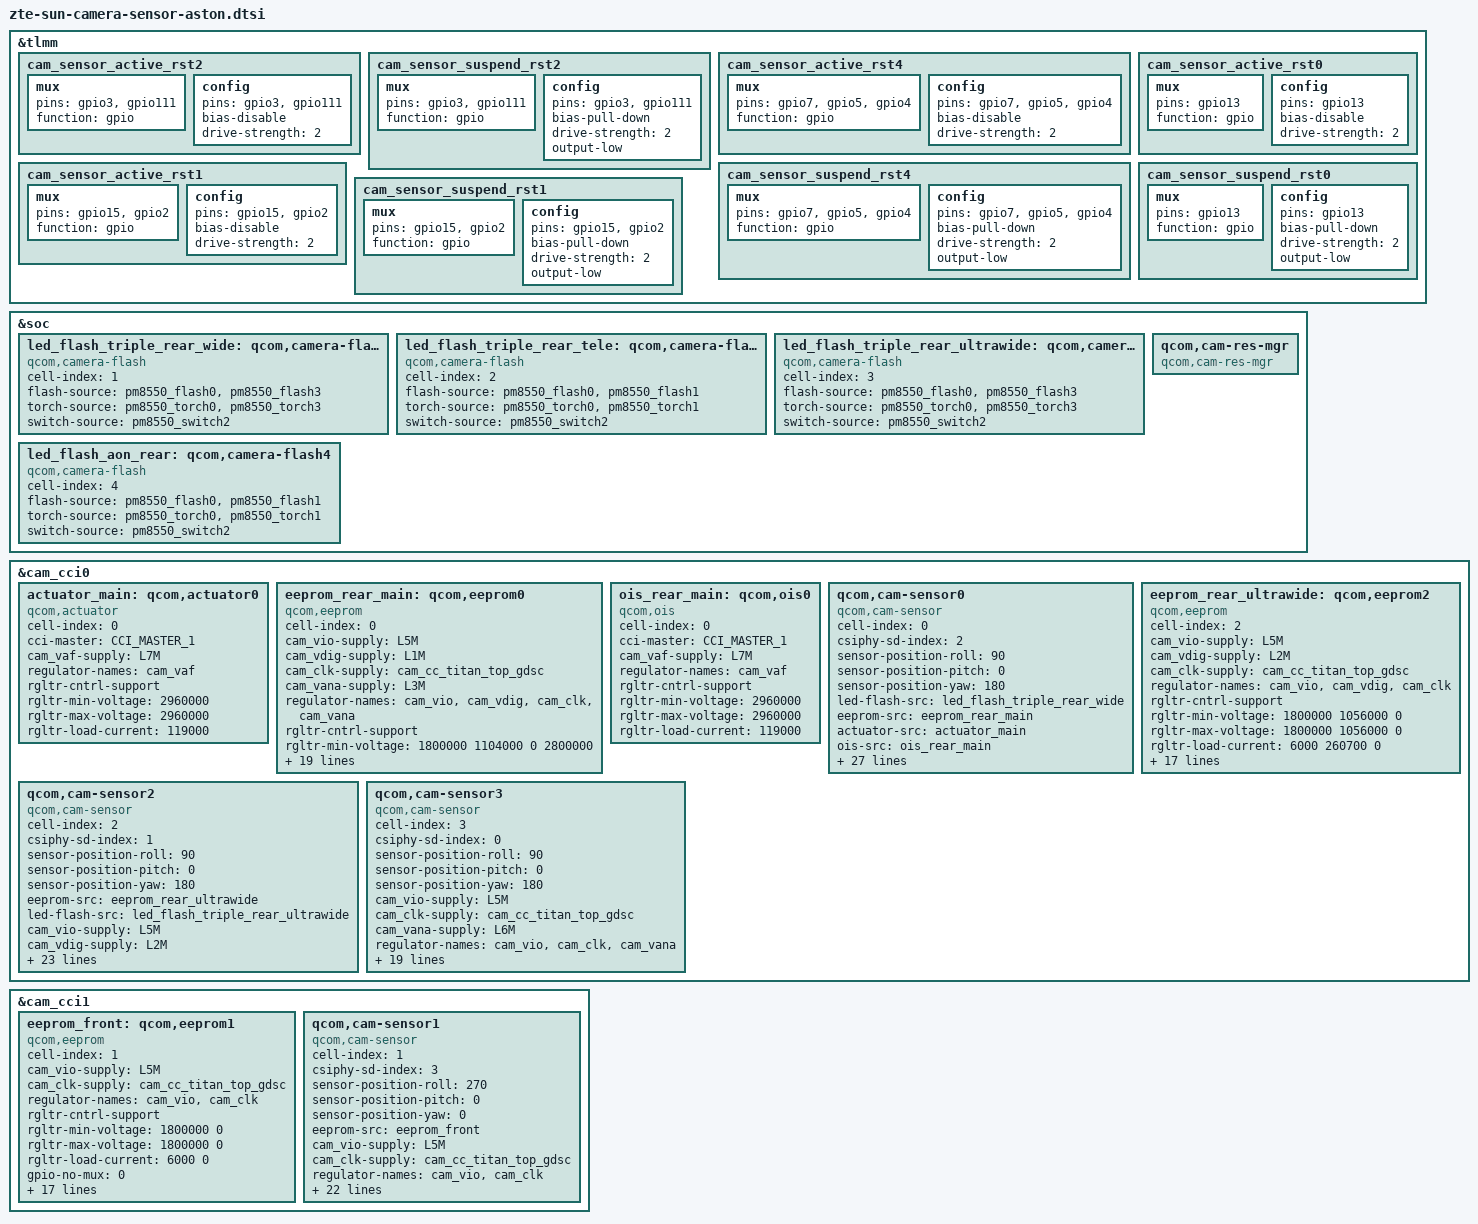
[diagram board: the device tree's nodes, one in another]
#include <dt-bindings/msm-camera.h>
&tlmm {
	cam_sensor_active_rst2: cam_sensor_active_rst2 {
		/* RESET 2 MAIN SENSOR*/
		mux {
			pins = "gpio3", "gpio111";
			function = "gpio";
		};

		config {
			pins = "gpio3", "gpio111";
			bias-disable; /* No PULL */
			drive-strength = <2>; /* 2 MA */
		};
	};

	cam_sensor_suspend_rst2: cam_sensor_suspend_rst2 {
		/* RESET 2 MAIN SENSOR*/
		mux {
			pins = "gpio3", "gpio111";
			function = "gpio";
		};

		config {
			pins = "gpio3", "gpio111";
			bias-pull-down; /* PULL DOWN */
			drive-strength = <2>; /* 2 MA */
			output-low;
		};
	};

	cam_sensor_active_rst4: cam_sensor_active_rst4 {
		/* RESET 4 FRONT SENSOR*/
		mux {
			pins = "gpio7", "gpio5", "gpio4";
			function = "gpio";
		};

		config {
			pins = "gpio7", "gpio5", "gpio4";
			bias-disable; /* No PULL */
			drive-strength = <2>; /* 2 MA */
		};
	};

	cam_sensor_suspend_rst4: cam_sensor_suspend_rst4 {
		/* RESET 4 FRONT SENSOR*/
		mux {
			pins = "gpio7", "gpio5", "gpio4";
			function = "gpio";
		};

		config {
			pins = "gpio7", "gpio5", "gpio4";
			bias-pull-down; /* PULL DOWN */
			drive-strength = <2>; /* 2 MA */
			output-low;
		};
	};

	cam_sensor_active_rst1: cam_sensor_active_rst1 {
		/* RESET 1 ULTRAWIDE SENSOR*/
		mux {
			pins = "gpio15", "gpio2";
			function = "gpio";
		};

		config {
			pins = "gpio15", "gpio2";
			bias-disable; /* No PULL */
			drive-strength = <2>; /* 2 MA */
		};
	};

	cam_sensor_suspend_rst1: cam_sensor_suspend_rst1 {
		/* RESET 1 ULTRAWIDE SENSOR*/
		mux {
			pins = "gpio15", "gpio2";
			function = "gpio";
		};

		config {
			pins = "gpio15", "gpio2";
			bias-pull-down; /* PULL DOWN */
			drive-strength = <2>; /* 2 MA */
			output-low;
		};
	};

	cam_sensor_active_rst0: cam_sensor_active_rst0 {
		/* RESET 0 WEIJU SENSOR*/
		mux {
			pins = "gpio13";
			function = "gpio";
		};

		config {
			pins = "gpio13";
			bias-disable; /* No PULL */
			drive-strength = <2>; /* 2 MA */
		};
	};

	cam_sensor_suspend_rst0: cam_sensor_suspend_rst0 {
		/* RESET 0 WEIJU SENSOR*/
		mux {
			pins = "gpio13";
			function = "gpio";
		};

		config {
			pins = "gpio13";
			bias-pull-down; /* PULL DOWN */
			drive-strength = <2>; /* 2 MA */
			output-low;
		};
	};

};

&soc {
	led_flash_triple_rear_wide: qcom,camera-flash1 {
		cell-index = <1>;
		compatible = "qcom,camera-flash";
		flash-source = <&pm8550_flash0 &pm8550_flash3>;
		torch-source = <&pm8550_torch0 &pm8550_torch3>;
		switch-source = <&pm8550_switch2>;
		status = "ok";
	};

	led_flash_triple_rear_tele: qcom,camera-flash2 {
		cell-index = <2>;
		compatible = "qcom,camera-flash";
		flash-source = <&pm8550_flash0 &pm8550_flash1>;
		torch-source = <&pm8550_torch0 &pm8550_torch1>;
		switch-source = <&pm8550_switch2>;
		status = "ok";
	};

	led_flash_triple_rear_ultrawide: qcom,camera-flash3 {
		cell-index = <3>;
		compatible = "qcom,camera-flash";
		flash-source = <&pm8550_flash0 &pm8550_flash3>;
		torch-source = <&pm8550_torch0 &pm8550_torch3>;
		switch-source = <&pm8550_switch2>;
		status = "ok";
	};

	led_flash_aon_rear: qcom,camera-flash4 {
		cell-index = <4>;
		compatible = "qcom,camera-flash";
		flash-source = <&pm8550_flash0 &pm8550_flash1>;
		torch-source = <&pm8550_torch0 &pm8550_torch1>;
		switch-source = <&pm8550_switch2>;
		status = "ok";
	};

	qcom,cam-res-mgr {
		compatible = "qcom,cam-res-mgr";
		status = "ok";
	};
};

&cam_cci0 {
//main
	actuator_main: qcom,actuator0 {
		cell-index = <0>;
		compatible = "qcom,actuator";
		cci-master = <CCI_MASTER_1>;
		cam_vaf-supply = <&L7M>;
		regulator-names = "cam_vaf";
		rgltr-cntrl-support;
		rgltr-min-voltage = <2960000>;
		rgltr-max-voltage = <2960000>;
		rgltr-load-current = <119000>;
	};

	eeprom_rear_main: qcom,eeprom0 {
		cell-index = <0>;
		compatible = "qcom,eeprom";
		cam_vio-supply = <&L5M>;
		cam_vdig-supply = <&L1M>;
		cam_clk-supply = <&cam_cc_titan_top_gdsc>;
		cam_vana-supply = <&L3M>;
		regulator-names = "cam_vio", "cam_vdig","cam_clk", "cam_vana";
		rgltr-cntrl-support;
		rgltr-min-voltage = <1800000 1104000 0 2800000>;
		rgltr-max-voltage = <1800000 1104000 0 2800000>;
		rgltr-load-current = <6000 454000 0 77900>;
		gpio-no-mux = <0>;
		pinctrl-names = "cam_default", "cam_suspend";
		pinctrl-0 = <&cam_sensor_mclk2_active
				 &cam_sensor_active_rst2>;
		pinctrl-1 = <&cam_sensor_mclk2_suspend
				 &cam_sensor_suspend_rst2>;
		gpios = <&tlmm 91 0>,
			<&tlmm 3 0>,
			<&tlmm 111 0>;
		gpio-reset = <1>;
		gpio-custom1 = <2>;
		gpio-req-tbl-num = <0 1 2>;
		gpio-req-tbl-flags = <1 0 0>;
		gpio-req-tbl-label = "CAMIF_MCLK2",
					"CAM_RESET2",
					"CAM_OISVDD2";
		cci-master = <CCI_MASTER_1>;
		clocks = <&cambistmclkcc CAM_BIST_MCLK_CC_MCLK2_CLK>;
		clock-names = "cam_clk";
		clock-cntl-level = "nominal";
		clock-rates = <24000000>;
		status = "ok";
	};

/* Started by AICoder, pid:h933b54111m1ff1144510a11a055bf161cf171c2 */
ois_rear_main: qcom,ois0 {
        cell-index = <0>;
        compatible = "qcom,ois";
        cci-master = <CCI_MASTER_1>;
        cam_vaf-supply = <&L7M>;
        regulator-names = "cam_vaf";
        rgltr-cntrl-support;
        rgltr-min-voltage = <2960000>;
        rgltr-max-voltage = <2960000>;
        rgltr-load-current = <119000>;
    };
/* Ended by AICoder, pid:h933b54111m1ff1144510a11a055bf161cf171c2 */

	qcom,cam-sensor0 {
		cell-index = <0>;
		compatible = "qcom,cam-sensor";
		csiphy-sd-index = <2>;
		sensor-position-roll = <90>;
		sensor-position-pitch = <0>;
		sensor-position-yaw = <180>;
		led-flash-src = <&led_flash_triple_rear_wide>;
		eeprom-src = <&eeprom_rear_main>;
		actuator-src = <&actuator_main>;
		ois-src = <&ois_rear_main>;
		cam_vio-supply = <&L5M>;
		cam_vdig-supply = <&L1M>;
		cam_clk-supply = <&cam_cc_titan_top_gdsc>;
		cam_vana-supply = <&L3M>;
		regulator-names = "cam_vio", "cam_vdig","cam_clk", "cam_vana";
		rgltr-cntrl-support;
		rgltr-min-voltage = <1800000 1104000 0 2800000>;
		rgltr-max-voltage = <1800000 1104000 0 2800000>;
		rgltr-load-current = <6000 454000 0 77900>;
		gpio-no-mux = <0>;
		pinctrl-names = "cam_default", "cam_suspend";
		pinctrl-0 = <&cam_sensor_mclk2_active
				 &cam_sensor_active_rst2>;
		pinctrl-1 = <&cam_sensor_mclk2_suspend
				 &cam_sensor_suspend_rst2>;
		gpios = <&tlmm 91 0>,
			<&tlmm 3 0>,
			<&tlmm 111 0>;
		gpio-reset = <1>;
		gpio-custom1 = <2>;
		gpio-req-tbl-num = <0 1 2>;
		gpio-req-tbl-flags = <1 0 0>;
		gpio-req-tbl-label = "CAMIF_MCLK2",
					"CAM_RESET2",
					"CAM_OISVDD2";
		cci-master = <CCI_MASTER_1>;
		clocks = <&cambistmclkcc CAM_BIST_MCLK_CC_MCLK2_CLK>;
		clock-names = "cam_clk";
		clock-cntl-level = "nominal";
		clock-rates = <24000000>;
		status = "ok";
	};

	eeprom_rear_ultrawide: qcom,eeprom2 {
		cell-index = <2>;
		compatible = "qcom,eeprom";
		cam_vio-supply = <&L5M>;
		cam_vdig-supply = <&L2M>;
		cam_clk-supply = <&cam_cc_titan_top_gdsc>;
		regulator-names = "cam_vio", "cam_vdig","cam_clk";
		rgltr-cntrl-support;
		rgltr-min-voltage = <1800000 1056000 0>;
		rgltr-max-voltage = <1800000 1056000 0>;
		rgltr-load-current = <6000 260700 0>;
		gpio-no-mux = <0>;
		pinctrl-names = "cam_default", "cam_suspend";
		pinctrl-0 = <&cam_sensor_mclk1_active
				 &cam_sensor_active_rst1>;
		pinctrl-1 = <&cam_sensor_mclk1_suspend
				 &cam_sensor_suspend_rst1>;
		gpios = <&tlmm 90 0>,
			<&tlmm 15 0>,
			<&tlmm 2 0>;
		gpio-reset = <1>;
		gpio-custom1 = <2>;
		gpio-req-tbl-num = <0 1 2>;
		gpio-req-tbl-flags = <1 0 0>;
		gpio-req-tbl-label = "CAMIF_MCLK1",
					"CAM_RESET1",
					"CAM_VANA1";
		cci-master = <CCI_MASTER_0>;
		clocks = <&cambistmclkcc CAM_BIST_MCLK_CC_MCLK1_CLK>;
		clock-names = "cam_clk";
		clock-cntl-level = "nominal";
		clock-rates = <24000000>;
		status = "ok";
	};

	qcom,cam-sensor2 {
		cell-index = <2>;
		compatible = "qcom,cam-sensor";
		csiphy-sd-index = <1>;
		sensor-position-roll = <90>;
		sensor-position-pitch = <0>;
		sensor-position-yaw = <180>;
		eeprom-src = <&eeprom_rear_ultrawide>;
		led-flash-src = <&led_flash_triple_rear_ultrawide>;
		cam_vio-supply = <&L5M>;
		cam_vdig-supply = <&L2M>;
		cam_clk-supply = <&cam_cc_titan_top_gdsc>;
		regulator-names = "cam_vio", "cam_vdig","cam_clk";
		rgltr-cntrl-support;
		rgltr-min-voltage = <1800000 1056000 0>;
		rgltr-max-voltage = <1800000 1056000 0>;
		rgltr-load-current = <6000 260700 0>;
		gpio-no-mux = <0>;
		pinctrl-names = "cam_default", "cam_suspend";
		pinctrl-0 = <&cam_sensor_mclk1_active
				 &cam_sensor_active_rst1>;
		pinctrl-1 = <&cam_sensor_mclk1_suspend
				 &cam_sensor_suspend_rst1>;
		gpios = <&tlmm 90 0>,
			<&tlmm 15 0>,
			<&tlmm 2 0>;
		gpio-reset = <1>;
		gpio-custom1 = <2>;
		gpio-req-tbl-num = <0 1 2>;
		gpio-req-tbl-flags = <1 0 0>;
		gpio-req-tbl-label = "CAMIF_MCLK1",
					"CAM_RESET1",
					"CAM_VANA1";
		cci-master = <CCI_MASTER_0>;
		clocks = <&cambistmclkcc CAM_BIST_MCLK_CC_MCLK1_CLK>;
		clock-names = "cam_clk";
		clock-cntl-level = "nominal";
		clock-rates = <24000000>;
		status = "ok";
	};

	qcom,cam-sensor3 {
		cell-index = <3>;
		compatible = "qcom,cam-sensor";
		csiphy-sd-index = <0>;
		sensor-position-roll = <90>;
		sensor-position-pitch = <0>;
		sensor-position-yaw = <180>;
		cam_vio-supply = <&L5M>;
		cam_clk-supply = <&cam_cc_titan_top_gdsc>;
		cam_vana-supply = <&L6M>;
		regulator-names = "cam_vio", "cam_clk", "cam_vana";
		rgltr-cntrl-support;
		rgltr-min-voltage = <1800000 0 2800000>;
		rgltr-max-voltage = <1800000 0 2800000>;
		rgltr-load-current = <6000 0 91400>;
		gpio-no-mux = <0>;
		pinctrl-names = "cam_default", "cam_suspend";
		pinctrl-0 = <&cam_sensor_mclk0_active
				 &cam_sensor_active_rst0>;
		pinctrl-1 = <&cam_sensor_mclk0_suspend
				 &cam_sensor_suspend_rst0>;
		gpios = <&tlmm 89 0>,
			<&tlmm 13 0>;
		gpio-reset = <1>;
		gpio-req-tbl-num = <0 1>;
		gpio-req-tbl-flags = <1 0>;
		gpio-req-tbl-label = "CAMIF_MCLK0",
					"CAM_RESET0";
		cci-master = <CCI_MASTER_0>;
		clocks = <&cambistmclkcc CAM_BIST_MCLK_CC_MCLK0_CLK>;
		clock-names = "cam_clk";
		clock-cntl-level = "nominal";
		clock-rates = <24000000>;
		status = "ok";
	};

};

&cam_cci1 {
//front
	eeprom_front: qcom,eeprom1 {
		cell-index = <1>;
		compatible = "qcom,eeprom";
		cam_vio-supply = <&L5M>;
		cam_clk-supply = <&cam_cc_titan_top_gdsc>;
		regulator-names = "cam_vio", "cam_clk";
		rgltr-cntrl-support;
		rgltr-min-voltage = <1800000 0>;
		rgltr-max-voltage = <1800000 0>;
		rgltr-load-current = <6000 0>;
		gpio-no-mux = <0>;
		pinctrl-names = "cam_default", "cam_suspend";
		pinctrl-0 = <&cam_sensor_mclk4_active
				 &cam_sensor_active_rst4>;
		pinctrl-1 = <&cam_sensor_mclk4_suspend
				 &cam_sensor_suspend_rst4>;
		gpios = <&tlmm 93 0>,
			<&tlmm 7 0>,
			<&tlmm 5 0>,
			<&tlmm 4 0>;
		gpio-reset = <1>;
		gpio-custom1 = <2>;
		gpio-custom2 = <3>;
		gpio-req-tbl-num = <0 1 2 3>;
		gpio-req-tbl-flags = <1 0 0 0>;
		gpio-req-tbl-label = "CAMIF_MCLK4",
					"CAM_RESET4",
					"CAM_VDIG4",
					"CAM_VANA4";
		cci-master = <CCI_MASTER_0>;
		clocks = <&cambistmclkcc CAM_BIST_MCLK_CC_MCLK4_CLK>;
		clock-names = "cam_clk";
		clock-cntl-level = "nominal";
		clock-rates = <24000000>;
		status = "ok";
	};

	qcom,cam-sensor1 {
		cell-index = <1>;
		compatible = "qcom,cam-sensor";
		csiphy-sd-index = <3>;
		sensor-position-roll = <270>;
		sensor-position-pitch = <0>;
		sensor-position-yaw = <0>;
		eeprom-src = <&eeprom_front>;
		cam_vio-supply = <&L5M>;
		cam_clk-supply = <&cam_cc_titan_top_gdsc>;
		regulator-names = "cam_vio", "cam_clk";
		rgltr-cntrl-support;
		rgltr-min-voltage = <1800000 0>;
		rgltr-max-voltage = <1800000 0>;
		rgltr-load-current = <6000 0>;
		gpio-no-mux = <0>;
		pinctrl-names = "cam_default", "cam_suspend";
		pinctrl-0 = <&cam_sensor_mclk4_active
				 &cam_sensor_active_rst4>;
		pinctrl-1 = <&cam_sensor_mclk4_suspend
				 &cam_sensor_suspend_rst4>;
		gpios = <&tlmm 93 0>,
			<&tlmm 7 0>,
			<&tlmm 5 0>,
			<&tlmm 4 0>;
		gpio-reset = <1>;
		gpio-custom1 = <2>;
		gpio-custom2 = <3>;
		gpio-req-tbl-num = <0 1 2 3>;
		gpio-req-tbl-flags = <1 0 0 0>;
		gpio-req-tbl-label = "CAMIF_MCLK4",
					"CAM_RESET4",
					"CAM_VDIG4",
					"CAM_VANA4";
		cci-master = <CCI_MASTER_0>;
		clocks = <&cambistmclkcc CAM_BIST_MCLK_CC_MCLK4_CLK>;
		clock-names = "cam_clk";
		clock-cntl-level = "nominal";
		clock-rates = <24000000>;
		status = "ok";
	};

};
